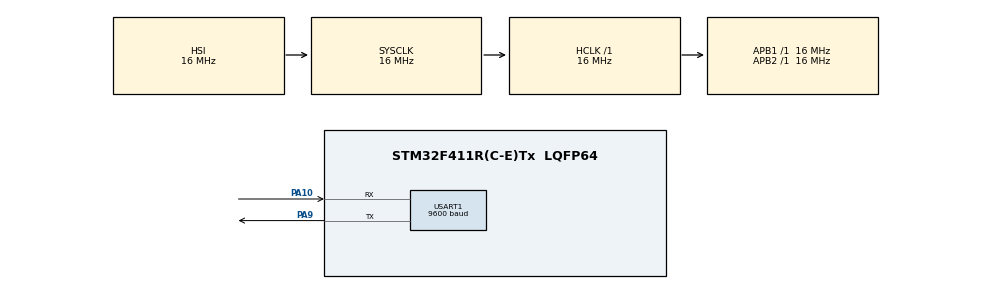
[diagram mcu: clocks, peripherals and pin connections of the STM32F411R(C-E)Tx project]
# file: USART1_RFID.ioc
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Mcu.Family=STM32F4
Mcu.Name=STM32F411R(C-E)Tx
Mcu.Package=LQFP64
NVIC.PriorityGroup=NVIC_PRIORITYGROUP_4
NVIC.USART1_IRQn=true\:0\:0\:false\:false\:true\:true\:true\:true
PA10.Mode=Asynchronous
PA10.Signal=USART1_RX
PA9.Mode=Asynchronous
PA9.Signal=USART1_TX
ProjectManager.HeapSize=0x200
ProjectManager.StackSize=0x400
ProjectManager.TargetToolchain=STM32CubeIDE
RCC.AHBFreq_Value=16000000
RCC.APB1Freq_Value=16000000
RCC.APB2Freq_Value=16000000
RCC.CortexFreq_Value=16000000
RCC.HSE_VALUE=25000000
RCC.HSI_VALUE=16000000
RCC.LSE_VALUE=32768
RCC.SYSCLKFreq_VALUE=16000000
RCC.VCOOutputFreq_Value=192000000
USART1.BaudRate=9600
USART1.VirtualMode=VM_ASYNC
board=custom

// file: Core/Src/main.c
/* USER CODE BEGIN Header */
/**
  ******************************************************************************
  * @file           : main.c
  * @brief          : Main program body
  ******************************************************************************
  * @attention
  *
  * Copyright (c) 2022 STMicroelectronics.
  * All rights reserved.
  *
  * This software is licensed under terms that can be found in the LICENSE file
  * in the root directory of this software component.
  * If no LICENSE file comes with this software, it is provided AS-IS.
  *
  ******************************************************************************
  */
/* USER CODE END Header */
#include "main.h"
#include"lcd.h"

UART_HandleTypeDef huart1;

void SystemClock_Config(void);
static void MX_GPIO_Init(void);
static void MX_USART1_UART_Init(void);

int main(void)
{
  /* USER CODE BEGIN 1 */
	uint8_t Rcvd_Data;
	uint8_t Data_Buffer[100];
	uint8_t count;
	char *USER_DATA="HEY!";

  /* USER CODE END 1 */

  /* MCU Configuration--------------------------------------------------------*/

  /* Reset of all peripherals, Initializes the Flash interface and the Systick. */
  HAL_Init();

  /* Configure the system clock */
  SystemClock_Config();

  /* Initialize all configured peripherals */
  MX_GPIO_Init();
  MX_USART1_UART_Init();
  /* USER CODE BEGIN 2 */
	while(1)
	{
		HAL_UART_Receive(&huart1, &Rcvd_Data, 1, HAL_MAX_DELAY);    //Read byte by byte

		if(Rcvd_Data == '\r')
		{
			//detect Return/Enter key
			Data_Buffer[count++] = '\r';
			break;
		}
		else
		{
//			Data_Buffer[count++] = Convert_To_Upper(Rcvd_Data);
			Data_Buffer[count++] = Rcvd_Data;
		}
	}

	LCD_init();
	delay(100);

  /* USER CODE END 2 */

  /* Infinite loop */
  while (1)
  {
	  if(Data_Buffer=="1800891E5CD3")
	  {
		  LCD_command(1);
		  char str[]={"Hey Sankalp!"};
//  		  strcpy(str,USER_DATA);
		  LCD_string(str);
		  delay(500);
//			  LCD_command(0xC0);
//  		  strcpy(str1,Data_Buffer);
//  		  LCD_string(str1);
//  		  LCD_command(1);
		  delay(500);
	  }
	  else if(Data_Buffer=="3E00684A4A56")
	  {
		  LCD_command(1);/* USER CODE BEGIN Header */
		  /**
		    **************************
		    * @file           : main.c
		    * @brief          : Main program body
		    **************************
		    * @attention
		    *
		    * Copyright (c) 2022 STMicroelectronics.
		    * All rights reserved.
		    *
		    * This software is licensed under terms that can be found in the LICENSE file
		    * in the root directory of this software component.
		    * If no LICENSE file comes with this software, it is provided AS-IS.
		    *
		    **************************
		    */
		  /* USER CODE END Header */
		  /* Includes ------------------------------------------------------------------*/
		  #include "main.h"
		  #include"string.h"
		  #include"LCD.h"
		  /* Private includes ----------------------------------------------------------*/

		  /* Private typedef -----------------------------------------------------------*/

		  /* Private define ------------------------------------------------------------*/

		  /* Private macro -------------------------------------------------------------*/

		  /* Private variables ---------------------------------------------------------*/
		  UART_HandleTypeDef huart1;

		  /* Private function prototypes -----------------------------------------------*/
		  void SystemClock_Config(void);
		  static void MX_GPIO_Init(void);
		  static void MX_USART1_UART_Init(void);

		  /* Private user code ---------------------------------------------------------*/

		  /**
		    * @brief  The application entry point.
		    * @retval int
		    */
		  int main(void)
		  {

		    /* USER CODE BEGIN 1 */
		  uint8_t Rcvd_Data;
		  uint8_t Data_Buffer[100];
		  uint8_t i;
		  char *USER_DATA="sankalp!";

		  //LCD_init();
		  //delay(10);

		  //while(1)
		  //{
		  //	char str[40];
		  //	strcpy(str,USER_DATA);
		  //	LCD_string(str);
		  //	delay(500);
		  ////	LCD_command(1);				//clear screen
		  ////	delay(500);
		  //	//LCD_command(1);
		  //	LCD_command(0xC0);
		  ////	char str1[] = {*USER_DATA};
		  ////	LCD_string(str1);
		  ////	delay(500);
		  //	LCD_command(1);
		  //	delay(500);
		  //}
		  ////uint32_t count=0;
		  //uint16_t USER_DATA;
		  //uint16_t len_of_data=strlen(userdat);
		    /* USER CODE END 1 */

		    /* MCU Configuration--------------------------------------------------------*/

		    /* Reset of all peripherals, Initializes the Flash interface and the Systick. */
		    HAL_Init();

		    /* Configure the system clock */
		    SystemClock_Config();

		    /* Initialize all configured peripherals */
		    MX_GPIO_Init();
		    MX_USART1_UART_Init();
		    HAL_UART_Transmit(&huart1, (uint8_t *)USER_DATA, strlen(USER_DATA), HAL_MAX_DELAY);
		    uint32_t count = 0;

		    /* Infinite loop */
		    /* USER CODE BEGIN WHILE */
		  	while(1)
		  	{
		  		HAL_UART_Receive(&huart1, &Rcvd_Data, 1, HAL_MAX_DELAY);    //Read byte by byte

		  		if(Rcvd_Data == '\r')
		  		{
		  			//detect Return/Enter key
		  			Data_Buffer[count++] = '\r';
		  			break;
		  		}
		  		else
		  		{
		  //			Data_Buffer[count++] = Convert_To_Upper(Rcvd_Data);
		  			Data_Buffer[count++] = Rcvd_Data;
		  		}
		  	}

		  	HAL_UART_Transmit(&huart1, (uint8_t*)Data_Buffer, count, HAL_MAX_DELAY);

		  	LCD_init();
		  	delay(10);

		  	while(1)
		  	{
		  			char str[40], str1[40];
		  			strcpy(str,USER_DATA);
		  			LCD_string(str);
		  			delay(500);
		  		//	LCD_command(1);				//clear screen
		  		//	delay(500);
		  			//LCD_command(1);
		  			LCD_command(0xC0);
		  			strcpy(str1,Data_Buffer);
		  		//	char str1[] = {*USER_DATA};
		  			LCD_string(str1);
		  		//	delay(500);
		  			LCD_command(1);
		  			delay(500);
		  	}
		  	return 0;

		    /* USER CODE END 3 */
		  }

		  /**
		    * @brief System Clock Configuration
		    * @retval None
		    */
		  void SystemClock_Config(void)
		  {
		    RCC_OscInitTypeDef RCC_OscInitStruct = {0};
		    RCC_ClkInitTypeDef RCC_ClkInitStruct = {0};

		    /** Configure the main internal regulator output voltage
		    */
		    __HAL_RCC_PWR_CLK_ENABLE();
		    __HAL_PWR_VOLTAGESCALING_CONFIG(PWR_REGULATOR_VOLTAGE_SCALE1);

		    /** Initializes the RCC Oscillators according to the specified parameters
		    * in the RCC_OscInitTypeDef structure.
		    */
		    RCC_OscInitStruct.OscillatorType = RCC_OSCILLATORTYPE_HSI;
		    RCC_OscInitStruct.HSIState = RCC_HSI_ON;
		    RCC_OscInitStruct.HSICalibrationValue = RCC_HSICALIBRATION_DEFAULT;
		    RCC_OscInitStruct.PLL.PLLState = RCC_PLL_NONE;
		    if (HAL_RCC_OscConfig(&RCC_OscInitStruct) != HAL_OK)
		    {
		      Error_Handler();
		    }

		    /** Initializes the CPU, AHB and APB buses clocks
		    */
		    RCC_ClkInitStruct.ClockType = RCC_CLOCKTYPE_HCLK|RCC_CLOCKTYPE_SYSCLK
		                                |RCC_CLOCKTYPE_PCLK1|RCC_CLOCKTYPE_PCLK2;
		    RCC_ClkInitStruct.SYSCLKSource = RCC_SYSCLKSOURCE_HSI;
		    RCC_ClkInitStruct.AHBCLKDivider = RCC_SYSCLK_DIV1;
		    RCC_ClkInitStruct.APB1CLKDivider = RCC_HCLK_DIV1;
		    RCC_ClkInitStruct.APB2CLKDivider = RCC_HCLK_DIV1;

		    if (HAL_RCC_ClockConfig(&RCC_ClkInitStruct, FLASH_LATENCY_0) != HAL_OK)
		    {
		      Error_Handler();
		    }
		  }

		  /**
		    * @brief USART1 Initialization Function
		    * @param None
		    * @retval None
		    */
		  static void MX_USART1_UART_Init(void)
		  {

		    huart1.Instance = USART1;
		    huart1.Init.BaudRate = 9600;
		    huart1.Init.WordLength = UART_WORDLENGTH_8B;
		    huart1.Init.StopBits = UART_STOPBITS_1;
		    huart1.Init.Parity = UART_PARITY_NONE;
		    huart1.Init.Mode = UART_MODE_TX_RX;
		    huart1.Init.HwFlowCtl = UART_HWCONTROL_NONE;
		    huart1.Init.OverSampling = UART_OVERSAMPLING_16;
		    if (HAL_UART_Init(&huart1) != HAL_OK)
		    {
		      Error_Handler();
		    }

		  }

		  /**
		    * @brief GPIO Initialization Function
		    * @param None
		    * @retval None
		    */
		  static void MX_GPIO_Init(void)
		  {

		    /* GPIO Ports Clock Enable */
		    __HAL_RCC_GPIOA_CLK_ENABLE();

		  }

		  /**
		    * @brief  This function is executed in case of error occurrence.
		    * @retval None
		    */
		  void Error_Handler(void)
		  {
		    __disable_irq();
		    while (1)
		    {
		    }
		  }

		  #ifdef  USE_FULL_ASSERT
		  /**
		    * @brief  Reports the name of the source file and the source line number
		    *         where the assert_param error has occurred.
		    * @param  file: pointer to the source file name
		    * @param  line: assert_param error line source number
		    * @retval None
		    */
		  void assert_failed(uint8_t *file, uint32_t line)
		  {
		  }
		  #endif /* USE_FULL_ASSERT */

		  char str[]={"Hey Naresh!"};
//  		  strcpy(str,USER_DATA);
		  LCD_string(str);
		  delay(500);
//			  LCD_command(0xC0);
//  		  strcpy(str1,Data_Buffer);
//  		  LCD_string(str1);
//  		  LCD_command(1);
		  delay(500);
	  }
	  else
	  {
		  LCD_command(1);
		  char str[]={"Hey Sandeep!"};
//  		  strcpy(str,USER_DATA);
		  LCD_string(str);
		  delay(500);
//			  LCD_command(0xC0);
//  		  strcpy(str1,Data_Buffer);
//  		  LCD_string(str1);
//  		  LCD_command(1);
		  delay(500);
	  }
}

void SystemClock_Config(void)
{
  RCC_OscInitTypeDef RCC_OscInitStruct = {0};
  RCC_ClkInitTypeDef RCC_ClkInitStruct = {0};

  /** Configure the main internal regulator output voltage
  */
  __HAL_RCC_PWR_CLK_ENABLE();
  __HAL_PWR_VOLTAGESCALING_CONFIG(PWR_REGULATOR_VOLTAGE_SCALE1);

  /** Initializes the RCC Oscillators according to the specified parameters
  * in the RCC_OscInitTypeDef structure.
  */
  RCC_OscInitStruct.OscillatorType = RCC_OSCILLATORTYPE_HSI;
  RCC_OscInitStruct.HSIState = RCC_HSI_ON;
  RCC_OscInitStruct.HSICalibrationValue = RCC_HSICALIBRATION_DEFAULT;
  RCC_OscInitStruct.PLL.PLLState = RCC_PLL_NONE;
  if (HAL_RCC_OscConfig(&RCC_OscInitStruct) != HAL_OK)
  {
    Error_Handler();
  }

  /** Initializes the CPU, AHB and APB buses clocks
  */
  RCC_ClkInitStruct.ClockType = RCC_CLOCKTYPE_HCLK|RCC_CLOCKTYPE_SYSCLK
                              |RCC_CLOCKTYPE_PCLK1|RCC_CLOCKTYPE_PCLK2;
  RCC_ClkInitStruct.SYSCLKSource = RCC_SYSCLKSOURCE_HSI;
  RCC_ClkInitStruct.AHBCLKDivider = RCC_SYSCLK_DIV1;
  RCC_ClkInitStruct.APB1CLKDivider = RCC_HCLK_DIV1;
  RCC_ClkInitStruct.APB2CLKDivider = RCC_HCLK_DIV1;

  if (HAL_RCC_ClockConfig(&RCC_ClkInitStruct, FLASH_LATENCY_0) != HAL_OK)
  {
    Error_Handler();
  }
}

static void MX_USART1_UART_Init(void)
{

  huart1.Instance = USART1;
  huart1.Init.BaudRate = 9600;
  huart1.Init.WordLength = UART_WORDLENGTH_8B;
  huart1.Init.StopBits = UART_STOPBITS_1;
  huart1.Init.Parity = UART_PARITY_NONE;
  huart1.Init.Mode = UART_MODE_TX_RX;
  huart1.Init.HwFlowCtl = UART_HWCONTROL_NONE;
  huart1.Init.OverSampling = UART_OVERSAMPLING_16;
  if (HAL_UART_Init(&huart1) != HAL_OK)
  {
    Error_Handler();
  }

}

static void MX_GPIO_Init(void)
{

  /* GPIO Ports Clock Enable */
  __HAL_RCC_GPIOA_CLK_ENABLE();

}

void Error_Handler(void)
{
  __disable_irq();
  while (1)
  {
  }
}
